# MKE14D7 register map
File version: 1.6
Registers are 32-bit, read-write, reset 0x0 unless marked. A register's access mark holds for its fields unless they carry their own. Offsets are from the block's base; [hi:lo] are bit positions; {n}, {i} and the like mark numbered series.

## EWM — External Watchdog Monitor
Base 0x40041000; register names take the prefix EWM_
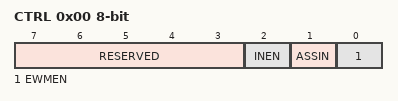
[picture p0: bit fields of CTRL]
0x00 CTRL 8-bit — Control Register
  [7:3] RESERVED ro
  [2] INEN — Input Enable.
  [1] ASSIN — EWM_in's Assertion State Select.
  [0] EWMEN — EWM enable.
0x01 SERV 8-bit wo — Service Register
  [7:0] SERVICE
0x02 CMPL 8-bit — Compare Low Register
  [7:0] COMPAREL
0x03 CMPH 8-bit reset 0xFF — Compare High Register
  [7:0] COMPAREH

## CMT — Carrier Modulator Transmitter
Base 0x40042000; register names take the prefix CMT_
0x00 CGH1 8-bit reset not defined — CMT Carrier Generator High Data Register 1
  [7:0] PH — Primary Carrier High Time Data Value
0x01 CGL1 8-bit reset not defined — CMT Carrier Generator Low Data Register 1
  [7:0] PL — Primary Carrier Low Time Data Value
0x02 CGH2 8-bit reset not defined — CMT Carrier Generator High Data Register 2
  [7:0] SH — Secondary Carrier High Time Data Value
0x03 CGL2 8-bit reset not defined — CMT Carrier Generator Low Data Register 2
  [7:0] SL — Secondary Carrier Low Time Data Value
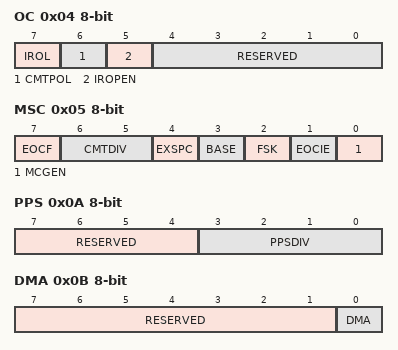
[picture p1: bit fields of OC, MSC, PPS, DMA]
0x04 OC 8-bit — CMT Output Control Register
  [7] IROL — IRO Latch Control
  [6] CMTPOL — CMT Output Polarity
    0=The IRO signal is active-low; 1=The IRO signal is active-high
  [5] IROPEN — IRO Pin Enable
    0=The IRO signal is disabled; 1=The IRO signal is enabled as output
  [4:0] RESERVED ro
0x05 MSC 8-bit — CMT Modulator Status and Control Register
  [7] EOCF ro — End Of Cycle Status Flag
    0=End of modulation cycle has not occured since the flag last cleared; 1=End of modulator cycle has occurred
  [6:5] CMTDIV — CMT Clock Divide Prescaler
    0=IF * 1; 1=IF * 2; 2=IF * 4; 3=IF * 8
  [4] EXSPC — Extended Space Enable
    0=Extended space is disabled; 1=Extended space is enabled
  [3] BASE — Baseband Enable
    0=Baseband mode is disabled; 1=Baseband mode is enabled
  [2] FSK — FSK Mode Select
    0=The CMT operates in Time or Baseband mode; 1=The CMT operates in FSK mode
  [1] EOCIE — End of Cycle Interrupt Enable
    0=CPU interrupt is disabled; 1=CPU interrupt is enabled
  [0] MCGEN — Modulator and Carrier Generator Enable
    0=Modulator and carrier generator disabled; 1=Modulator and carrier generator enabled
0x06 CMD1 8-bit reset not defined — CMT Modulator Data Register Mark High
  [7:0] MB
0x07 CMD2 8-bit reset not defined — CMT Modulator Data Register Mark Low
  [7:0] MB
0x08 CMD3 8-bit reset not defined — CMT Modulator Data Register Space High
  [7:0] SB
0x09 CMD4 8-bit reset not defined — CMT Modulator Data Register Space Low
  [7:0] SB
0x0A PPS 8-bit — CMT Primary Prescaler Register
  [7:4] RESERVED ro
  [3:0] PPSDIV — Primary Prescaler Divider
    {v}=Bus clock * {v+1} (v=0..15)
0x0B DMA 8-bit — CMT Direct Memory Access Register
  [7:1] RESERVED ro
  [0] DMA — DMA Enable
    0=DMA transfer request and done are disabled; 1=DMA transfer request and done are enabled

## ICS — Internal clock source
Base 0x40044000; register names take the prefix ICS_
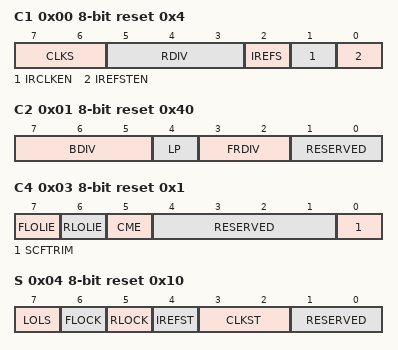
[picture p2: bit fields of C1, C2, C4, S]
0x00 C1 8-bit reset 0x4 — ICS Control Register 1
  [7:6] CLKS — Clock Source Select
    0=Output of FLL is selected; 1=Internal reference clock is selected; 2=External reference clock is selected; 3=Reserved, defaults to 00
  [5:3] RDIV — Reference Divider
  [2] IREFS — Internal Reference Select
    0=External reference clock selected; 1=Internal reference clock selected
  [1] IRCLKEN — Internal Reference Clock Enable
    0=ICSIRCLK inactive; 1=ICSIRCLK active
  [0] IREFSTEN — Internal Reference Stop Enable
    0=Internal reference clock is disabled in stop; 1=Internal reference clock stays enabled in stop if IRCLKEN is set before entering stop
0x01 C2 8-bit reset 0x40 — ICS Control Register 2
  [7:5] BDIV — Bus Frequency Divider
    0=Encoding 0 - Divides selected clock by 1. This value can not be written or readback in some devices.; 1=Encoding 1 - Divides selected clock by 2; 2=Encoding 2 - Divides selected clock by 4 (reset default); 3=Encoding 3 - Divides selected clock by 8; 4=Encoding 4 - Divides selected clock by 16; 5=Encoding 5 - Divides selected clock by 32; 6=Encoding 6 - Divides selected clock by 64; 7=Encoding 7 - Divides selected clock by 128
  [4] LP — Low Power Select
    0=FLL is not disabled in bypass mode; 1=FLL is disabled in bypass modes unless BDM is active
  [3:2] FRDIV — Fine Reference Divider
  [1:0] RESERVED ro
0x02 C3 8-bit reset not defined — ICS Control Register 3
  [7:0] SCTRIM — Slow Internal Reference Clock Trim Setting
0x03 C4 8-bit reset 0x1 — ICS Control Register 4
  [7] FLOLIE — Loss of Fine Lock Interrupt Enable
    0=Lose of fine Lock Interrupt disable; 1=Lose of fine Lock Interrupt enable
  [6] RLOLIE — Loss of Rough Lock Interrupt Enable
    0=Lose of Rough Lock Interrupt disable; 1=Lose of Rough Lock Interrupt enable
  [5] CME — Clock Monitor Enable
    0=Clock monitor is disabled; 1=Clock monitor enable
  [4:1] RESERVED ro
  [0] SCFTRIM — Slow Internal Reference Clock Fine Trim
0x04 S 8-bit ro reset 0x10 — ICS Status Register
  [7] LOLS — Loss of Lock Status
    0=FLL has not lost lock since LOLS was last cleared; 1=FLL has lost lock since LOLS was last cleared
  [6] FLOCK — Fine Lock Status
    0=FLL is currently unlocked; 1=FLL is currently locked
  [5] RLOCK — Rough Lock Status
    0=FLL is currently Roughly unlocked or FLL is disabled; 1=FLL is currently Roughly locked
  [4] IREFST — Internal Reference Status
    0=Source of reference clock is external clock; 1=Source of reference clock is internal clock
  [3:2] CLKST — Clock Mode Status
    0=Output of FLL is selected; 1=FLL Bypassed, internal reference clock is selected; 2=FLL Bypassed, external reference clock is selected
  [1:0] RESERVED
